VERSION ""

NS_ :

BS_:

BU_: XXX

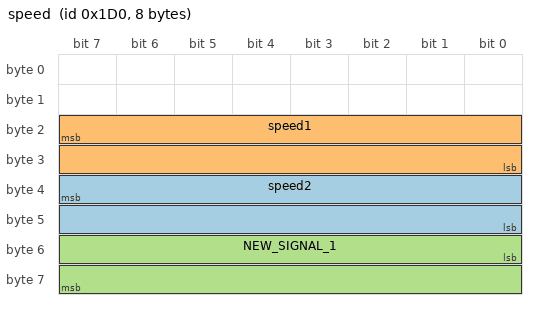
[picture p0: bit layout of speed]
BO_ 464 speed: 8 XXX
 SG_ speed2 : 39|16@0+ (1,0) [0|65535] "" XXX
 SG_ speed1 : 23|16@0+ (1,0) [0|65535] "" XXX
 SG_ NEW_SIGNAL_1 : 48|16@1- (1,0) [0|65535] "" XXX

BO_ 406 NEW_MSG_2: 8 XXX

BO_ 310 NEW_MSG_3: 8 XXX

BO_ 319 NEW_MSG_4: 8 XXX

BO_ 344 NEW_MSG_5: 8 XXX

BO_ 380 NEW_MSG_6: 8 XXX

BO_ 208 NEW_MSG_7: 8 XXX

BO_ 356 NEW_MSG_8: 8 XXX
 SG_ NEW_SIGNAL_1 : 31|16@0+ (1,0) [0|65535] "" XXX
 SG_ NEW_SIGNAL_2 : 47|16@0+ (1,0) [0|65535] "" XXX
